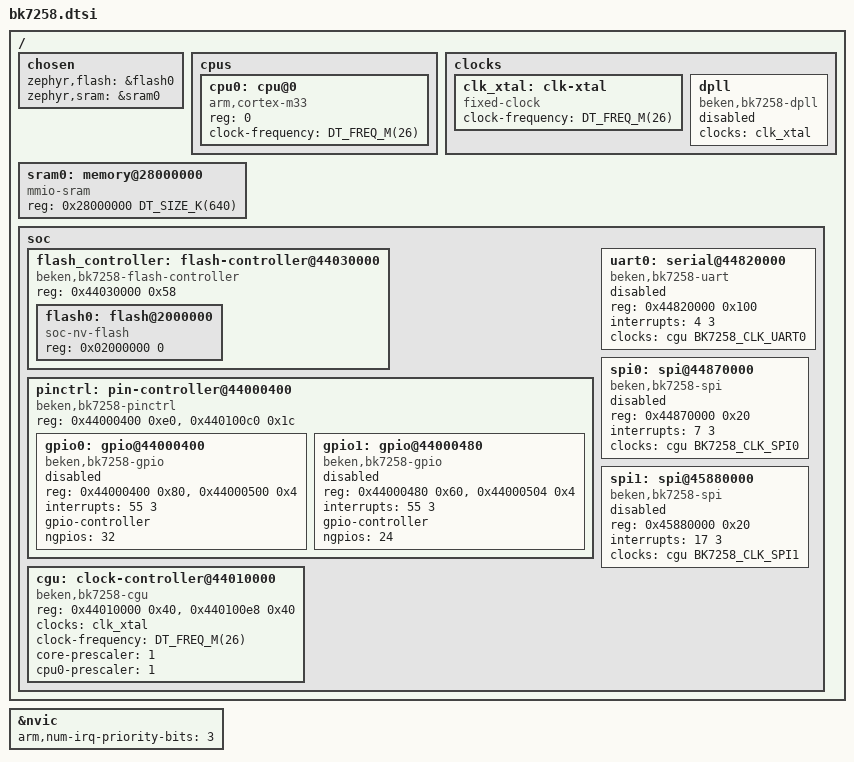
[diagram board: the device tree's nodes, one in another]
/*
 * Copyright The Zephyr Project Contributors
 *
 * SPDX-License-Identifier: Apache-2.0
 */

#include <freq.h>
#include <mem.h>
#include <arm/armv8-m.dtsi>
#include <zephyr/dt-bindings/clock/beken_bk7258_clock.h>

/ {
	chosen {
		zephyr,flash = &flash0;
		zephyr,sram = &sram0;
	};

	cpus {
		#address-cells = <1>;
		#size-cells = <0>;

		/*
		 * The rate SysTick counts, which has to agree with what the
		 * clock controller is told to program; the driver asserts
		 * that at build time. This is what the BootROM leaves, since
		 * Zephyr is started directly by the ROM.
		 */
		cpu0: cpu@0 {
			device_type = "cpu";
			compatible = "arm,cortex-m33";
			reg = <0>;
			clock-frequency = <DT_FREQ_M(26)>;
		};
	};

	clocks {
		/*
		 * The crystal every board carries, and the DPLL. The DPLL is
		 * left powered down by the BootROM, so a board that wants it
		 * enables it and points the clock controller at the output it
		 * wants.
		 */
		clk_xtal: clk-xtal {
			#clock-cells = <0>;
			compatible = "fixed-clock";
			clock-frequency = <DT_FREQ_M(26)>;
		};

		dpll: dpll {
			#clock-cells = <1>;
			compatible = "beken,bk7258-dpll";
			clocks = <&clk_xtal>;
			status = "disabled";
		};
	};

	/*
	 * SRAM banks 0 to 5, contiguous. The whole block is claimed here
	 * because CPU1 and CPU2 are left unbooted; it has to be split once
	 * they are used.
	 */
	sram0: memory@28000000 {
		compatible = "mmio-sram";
		reg = <0x28000000 DT_SIZE_K(640)>;
	};

	soc {
		flash_controller: flash-controller@44030000 {
			compatible = "beken,bk7258-flash-controller";
			reg = <0x44030000 0x58>;
			#address-cells = <1>;
			#size-cells = <1>;
			ranges;

			/*
			 * Flash as the CPU sees it through the execute-in-place
			 * window. Zephyr is the first stage, so it starts at the
			 * base of the window. How much is there is a property of
			 * the board, which sets the size.
			 */
			flash0: flash@2000000 {
				compatible = "soc-nv-flash";
				reg = <0x02000000 0>;
				#address-cells = <1>;
				#size-cells = <1>;
			};
		};

		/*
		 * Pads are configured in the AON GPIO block, one word per
		 * pad, and switched between functions by seven words in the
		 * SYS block that the clock controller sits in too.
		 */
		pinctrl: pin-controller@44000400 {
			compatible = "beken,bk7258-pinctrl";
			reg = <0x44000400 0xe0>, <0x440100c0 0x1c>;
			reg-names = "pad", "func";
			#address-cells = <1>;
			#size-cells = <1>;
			ranges;

			gpio0: gpio@44000400 {
				compatible = "beken,bk7258-gpio";
				reg = <0x44000400 0x80>, <0x44000500 0x4>;
				reg-names = "pad", "int_status";
				interrupts = <55 3>;
				gpio-controller;
				#gpio-cells = <2>;
				ngpios = <32>;
				status = "disabled";
			};

			gpio1: gpio@44000480 {
				compatible = "beken,bk7258-gpio";
				reg = <0x44000480 0x60>, <0x44000504 0x4>;
				reg-names = "pad", "int_status";
				interrupts = <55 3>;
				gpio-controller;
				#gpio-cells = <2>;
				ngpios = <24>;
				status = "disabled";
			};
		};

		/*
		 * Clock selects, dividers and gates, then the analog block:
		 * the analog SPI status word followed by the registers that
		 * hold the DPLL and core-voltage settings.
		 *
		 * "clocks" is the core clock's source and "clock-frequency"
		 * the rate CPU0 ends up at, which is the source divided by
		 * core-prescaler and then by cpu0-prescaler. This is what the
		 * BootROM leaves: the crystal, undivided.
		 */
		cgu: clock-controller@44010000 {
			compatible = "beken,bk7258-cgu";
			reg = <0x44010000 0x40>, <0x440100e8 0x40>;
			reg-names = "cgu", "ana";
			clocks = <&clk_xtal>;
			clock-frequency = <DT_FREQ_M(26)>;
			core-prescaler = <1>;
			cpu0-prescaler = <1>;
			#clock-cells = <1>;
		};

		uart0: serial@44820000 {
			compatible = "beken,bk7258-uart";
			reg = <0x44820000 0x100>;
			interrupts = <4 3>;
			clocks = <&cgu BK7258_CLK_UART0>;
			status = "disabled";
		};

		spi0: spi@44870000 {
			compatible = "beken,bk7258-spi";
			reg = <0x44870000 0x20>;
			interrupts = <7 3>;
			clocks = <&cgu BK7258_CLK_SPI0>;
			#address-cells = <1>;
			#size-cells = <0>;
			status = "disabled";
		};

		spi1: spi@45880000 {
			compatible = "beken,bk7258-spi";
			reg = <0x45880000 0x20>;
			interrupts = <17 3>;
			clocks = <&cgu BK7258_CLK_SPI1>;
			#address-cells = <1>;
			#size-cells = <0>;
			status = "disabled";
		};
	};
};

&nvic {
	arm,num-irq-priority-bits = <3>;
};
